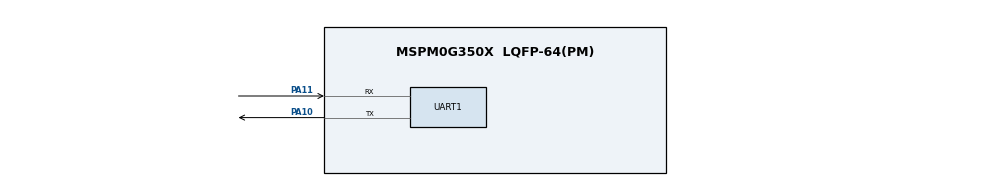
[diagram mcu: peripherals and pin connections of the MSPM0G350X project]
/**
 * @cliArgs --device "MSPM0G350X" --part "Default" --package "LQFP-64(PM)" --product "mspm0_sdk@2.11.00.07"
 * @versions {"tool":"1.26.2+4477"}
 */

/**
 * Import the modules used in this configuration.
 */
const ADC12         = scripting.addModule("/ti/driverlib/ADC12", {}, false);
const ADC121        = ADC12.addInstance();
const DAC12         = scripting.addModule("/ti/driverlib/DAC12");
const GPIO          = scripting.addModule("/ti/driverlib/GPIO", {}, false);
const GPIO1         = GPIO.addInstance();
const SYSCTL        = scripting.addModule("/ti/driverlib/SYSCTL");
const TIMER         = scripting.addModule("/ti/driverlib/TIMER", {}, false);
const TIMER1        = TIMER.addInstance();
const TIMER2        = TIMER.addInstance();
const UART          = scripting.addModule("/ti/driverlib/UART", {}, false);
const UART1         = UART.addInstance();
const ProjectConfig = scripting.addModule("/ti/project_config/ProjectConfig");

/**
 * Write custom configuration values to the imported modules.
 */
const gate8  = system.clockTree["MFPCLKGATE"];
gate8.enable = true;

ADC121.$name                      = "ADC12_0";
ADC121.sampleTime0                = "0.001 ms";
ADC121.interruptPriority          = "3";
ADC121.powerDownMode              = "DL_ADC12_POWER_DOWN_MODE_MANUAL";
ADC121.adcPin0Config.$name        = "ti_driverlib_gpio_GPIOPinGeneric2";
ADC121.adcPin0Config.enableConfig = true;

const Board = scripting.addModule("/ti/driverlib/Board", {}, false);


GPIO1.$name                                 = "GPIO_LEDS";
GPIO1.associatedPins.create(4);
GPIO1.associatedPins[0].initialValue        = "SET";
GPIO1.associatedPins[0].$name               = "S1";
GPIO1.associatedPins[0].direction           = "INPUT";
GPIO1.associatedPins[0].assignedPort        = "PORTA";
GPIO1.associatedPins[0].assignedPin         = "18";
GPIO1.associatedPins[0].assignedPortSegment = "Upper";
GPIO1.associatedPins[0].internalResistor    = "PULL_DOWN";
GPIO1.associatedPins[1].$name               = "RGB_RED";
GPIO1.associatedPins[1].assignedPort        = "PORTB";
GPIO1.associatedPins[1].assignedPortSegment = "Upper";
GPIO1.associatedPins[1].assignedPin         = "22";
GPIO1.associatedPins[2].$name               = "RGB_BLUE";
GPIO1.associatedPins[2].assignedPort        = "PORTB";
GPIO1.associatedPins[2].assignedPortSegment = "Upper";
GPIO1.associatedPins[2].assignedPin         = "26";
GPIO1.associatedPins[3].$name               = "RGB_GREEN";
GPIO1.associatedPins[3].assignedPort        = "PORTB";
GPIO1.associatedPins[3].assignedPortSegment = "Upper";
GPIO1.associatedPins[3].assignedPin         = "27";

SYSCTL.clockTreeEn = true;
SYSCTL.MFPCLKEn    = true;

TIMER1.$name       = "TIMER_0";
TIMER1.timerMode   = "PERIODIC_UP";
TIMER1.timerPeriod = "2.048 ms";
TIMER1.interrupts  = ["ZERO"];

TIMER2.$name             = "TIMER_1";
TIMER2.timerPeriod       = "5 ms";
TIMER2.timerMode         = "PERIODIC_UP";
TIMER2.timerClkPrescale  = 3;
TIMER2.interrupts        = ["ZERO"];
TIMER2.interruptPriority = "3";

UART1.$name                    = "UART_0";
UART1.targetBaudRate           = 115200;
UART1.peripheral.rxPin.$assign = "PA11";
UART1.peripheral.txPin.$assign = "PA10";
UART1.txPinConfig.$name        = "ti_driverlib_gpio_GPIOPinGeneric0";
UART1.rxPinConfig.$name        = "ti_driverlib_gpio_GPIOPinGeneric1";

ProjectConfig.genDisable = true;

/**
 * Pinmux solution for unlocked pins/peripherals. This ensures that minor changes to the automatic solver in a future
 * version of the tool will not impact the pinmux you originally saw.  These lines can be completely deleted in order to
 * re-solve from scratch.
 */
ADC121.peripheral.$suggestSolution           = "ADC1";
ADC121.peripheral.adcPin0.$suggestSolution   = "PA15";
Board.peripheral.$suggestSolution            = "DEBUGSS";
Board.peripheral.swclkPin.$suggestSolution   = "PA20";
Board.peripheral.swdioPin.$suggestSolution   = "PA19";
DAC12.peripheral.$suggestSolution            = "DAC0";
GPIO1.associatedPins[0].pin.$suggestSolution = "PA18";
GPIO1.associatedPins[1].pin.$suggestSolution = "PB22";
GPIO1.associatedPins[2].pin.$suggestSolution = "PB26";
GPIO1.associatedPins[3].pin.$suggestSolution = "PB27";
TIMER1.peripheral.$suggestSolution           = "TIMA1";
TIMER2.peripheral.$suggestSolution           = "TIMA0";
UART1.peripheral.$suggestSolution            = "UART0";
